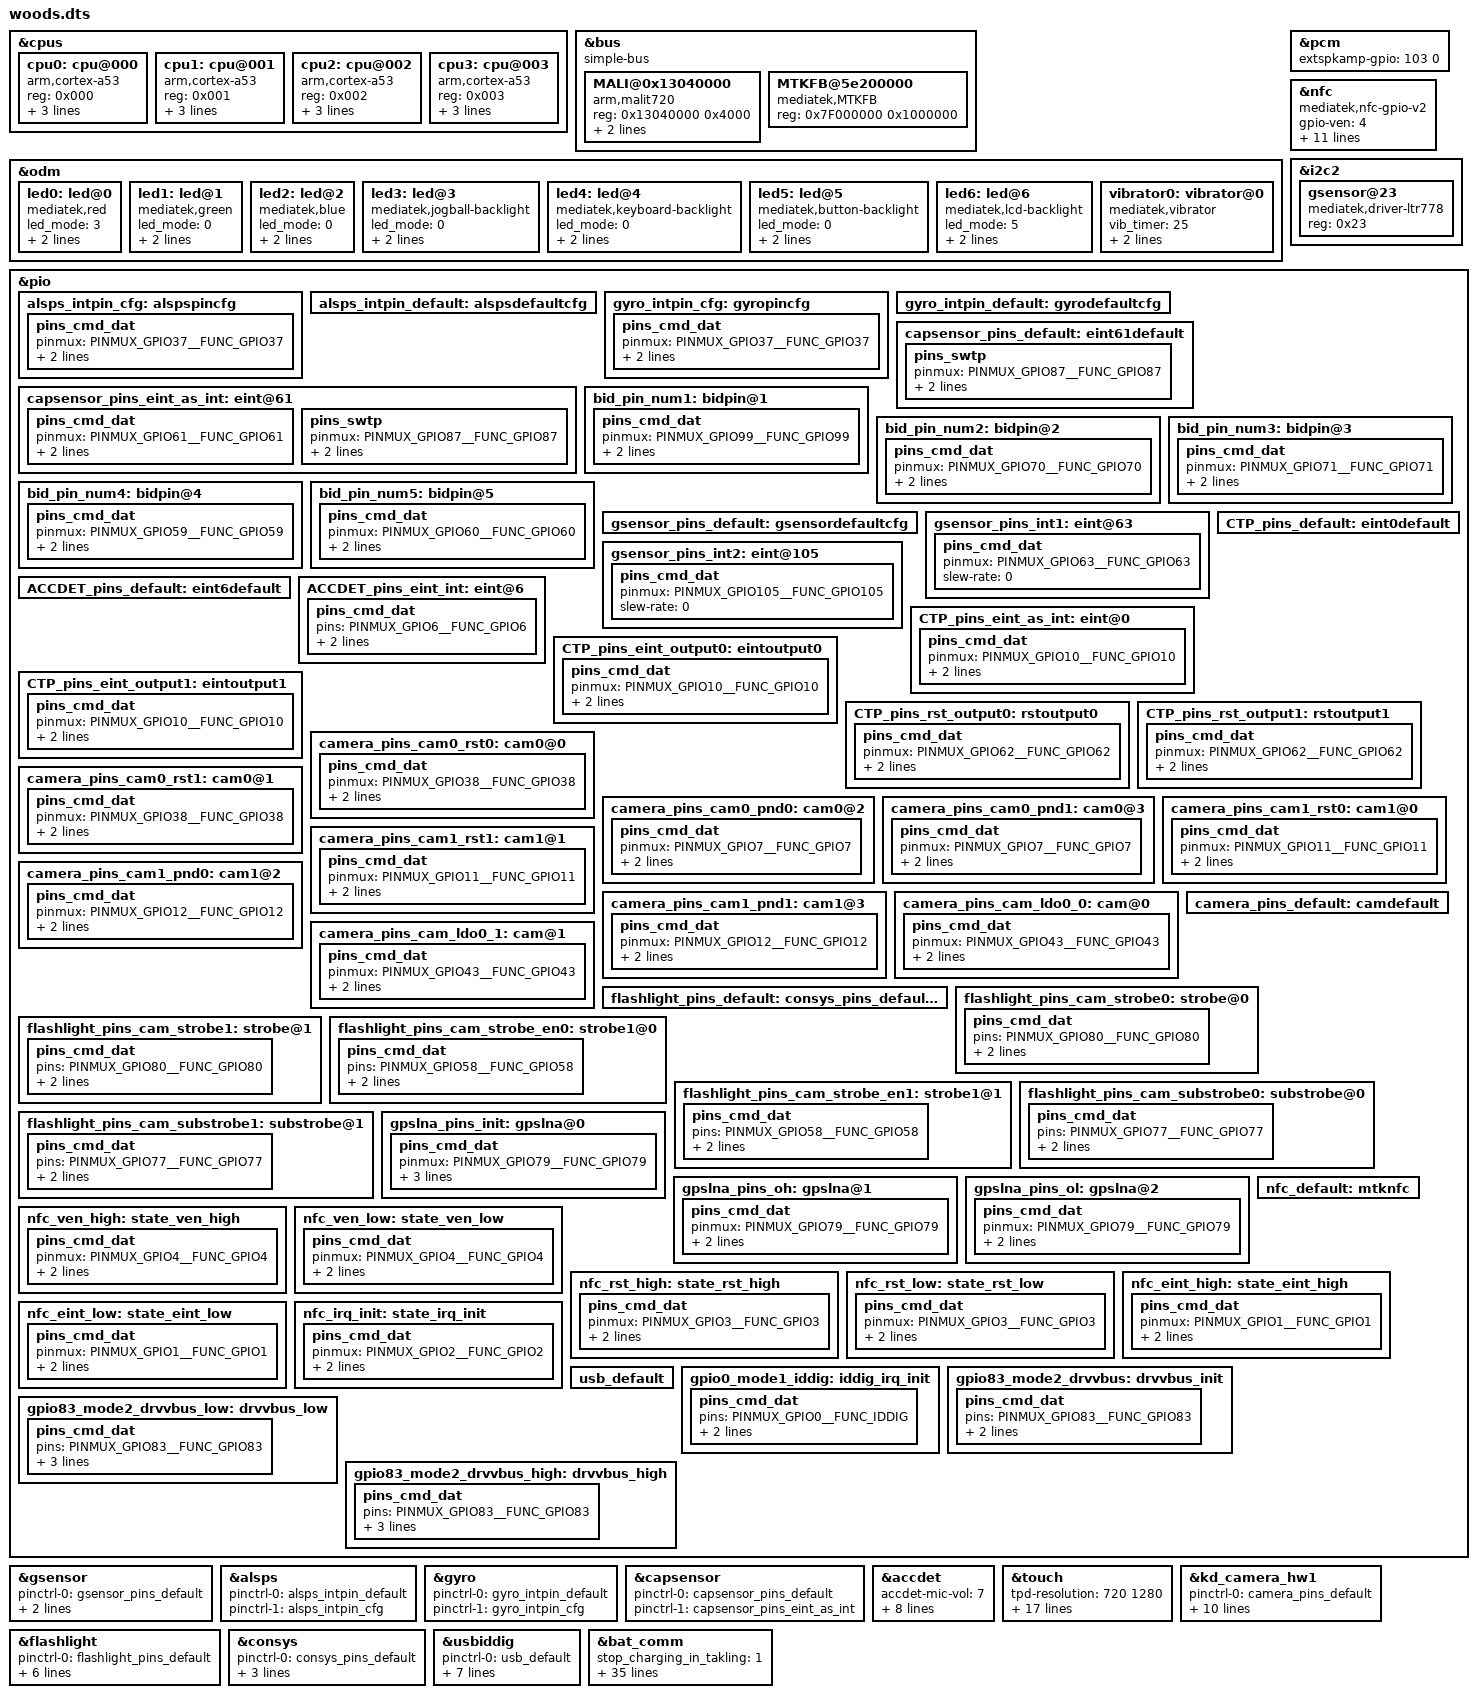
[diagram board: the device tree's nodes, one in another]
#include <generated/autoconf.h>
/dts-v1/;

#include "mt6735m.dts"

&cpus {
	#address-cells = <1>;
	#size-cells = <0>;
	/*enable-method = "mediatek,mt6735-smp"; */

	cpu0: cpu@000 {
		device_type = "cpu";
		compatible = "arm,cortex-a53";
		reg = <0x000>;
		enable-method = "spin-table";
		cpu-release-addr = <0x0 0x40000200>;
		clock-frequency = <1100000000>;
	};

	cpu1: cpu@001 {
		device_type = "cpu";
		compatible = "arm,cortex-a53";
		reg = <0x001>;
		enable-method = "spin-table";
		cpu-release-addr = <0x0 0x40000200>;
		clock-frequency = <1100000000>;
	};

	cpu2: cpu@002 {
		device_type = "cpu";
		compatible = "arm,cortex-a53";
		reg = <0x002>;
		enable-method = "spin-table";
		cpu-release-addr = <0x0 0x40000200>;
		clock-frequency = <1100000000>;
	};

	cpu3: cpu@003 {
		device_type = "cpu";
		compatible = "arm,cortex-a53";
		reg = <0x003>;
		enable-method = "spin-table";
		cpu-release-addr = <0x0 0x40000200>;
		clock-frequency = <1100000000>;
	};
};

&bus {
	compatible = "simple-bus";
	#address-cells = <1>;
	#size-cells = <1>;
	ranges = <0 0 0 0xffffffff>;

	MALI@0x13040000 {
		compatible = "arm,malit720", "arm,mali-t72x", "arm,malit7xx", "arm,mali-midgard";
		reg = <0x13040000 0x4000>;
		interrupts = <0 212 0x8>, <0 211 0x8>, <0 210 0x8>;
		interrupt-names = "JOB", "MMU", "GPU";
		clock-frequency = <550000000>;
	};

	MTKFB@5e200000 {
		compatible = "mediatek,MTKFB";
		reg = <0x7F000000 0x1000000>;
	};
};

&odm {
	led0:led@0 {
		compatible = "mediatek,red";
		led_mode = <3>;
		data = <2>;
		pwm_config = <0 0 0 0 0>;
	};
	led1:led@1 {
		compatible = "mediatek,green";
		led_mode = <0>;
		data = <1>;
		pwm_config = <0 0 0 0 0>;
	};
	led2:led@2 {
		compatible = "mediatek,blue";
		led_mode = <0>;
		data = <1>;
		pwm_config = <0 0 0 0 0>;
	};
	led3:led@3 {
		compatible = "mediatek,jogball-backlight";
		led_mode = <0>;
		data = <1>;
		pwm_config = <0 0 0 0 0>;
	};
	led4:led@4 {
		compatible = "mediatek,keyboard-backlight";
		led_mode = <0>;
		data = <1>;
		pwm_config = <0 0 0 0 0>;
	};
	led5:led@5 {
		compatible = "mediatek,button-backlight";
		led_mode = <0>;
		data = <1>;
		pwm_config = <0 0 0 0 0>;
	};
	led6:led@6 {
		compatible = "mediatek,lcd-backlight";
		led_mode = <5>;
		data = <1>;
		pwm_config = <0 0 0 0 0>;
	};
	vibrator0:vibrator@0 {
		compatible = "mediatek,vibrator";
		vib_timer = <25>;
		vib_limit = <9>;
		vib_vol= <5>;
	};
};

&pcm {
    extspkamp-gpio = <103 0>;
};

&nfc {
    compatible = "mediatek,nfc-gpio-v2";
    gpio-ven = <4>;
    gpio-rst = <3>;
    gpio-eint = <1>;
    gpio-irq = <2>;
};


&i2c2 {
	#address-cells = <1>;
	#size-cells = <0>;
	gsensor@23 {
		compatible = "mediatek,driver-ltr778";
		reg = <0x23>;
		status = "okay";
	};
};

/* sensor gpio standization */
&pio {
	alsps_intpin_cfg: alspspincfg {

		pins_cmd_dat {
			pinmux = <PINMUX_GPIO37__FUNC_GPIO37>;
			slew-rate = <0>;
			bias-pull-up = <00>;
		};
	};

	alsps_intpin_default: alspsdefaultcfg {

	};

	gyro_intpin_cfg: gyropincfg {

		pins_cmd_dat {
			pinmux = <PINMUX_GPIO37__FUNC_GPIO37>;
			slew-rate = <0>;
			bias-pull-down = <00>;
		};
	};

	gyro_intpin_default: gyrodefaultcfg {

	};

	capsensor_pins_default: eint61default {
		pins_swtp {
		    pinmux = <PINMUX_GPIO87__FUNC_GPIO87>;
		    slew-rate = <0>;
		    bias-pull-up = <00>;
		};
	};
	capsensor_pins_eint_as_int: eint@61 {
		pins_cmd_dat {
			pinmux = <PINMUX_GPIO61__FUNC_GPIO61>;
			slew-rate = <0>;
			bias-pull-up = <00>;
		};
        pins_swtp {
            pinmux = <PINMUX_GPIO87__FUNC_GPIO87>;
            slew-rate = <0>;
            bias-pull-up = <00>;
        };
	};

};

&pio {
	bid_pin_num1: bidpin@1 {
	    pins_cmd_dat {
			pinmux = <PINMUX_GPIO99__FUNC_GPIO99>;
			slew-rate = <1>;
			bias-pull-down = <00>;
		};
	};
	bid_pin_num2: bidpin@2 {
	    pins_cmd_dat {
			pinmux = <PINMUX_GPIO70__FUNC_GPIO70>;
			slew-rate = <1>;
			bias-pull-down = <00>;
		};
	};
	bid_pin_num3: bidpin@3 {
	    pins_cmd_dat {
			pinmux = <PINMUX_GPIO71__FUNC_GPIO71>;
			slew-rate = <1>;
			bias-pull-down = <00>;
		};
	};
	bid_pin_num4: bidpin@4{
	    pins_cmd_dat {
			pinmux = <PINMUX_GPIO59__FUNC_GPIO59>;
			slew-rate = <1>;
			bias-pull-down = <00>;
		};
	};
	bid_pin_num5: bidpin@5 {
	    pins_cmd_dat {
			pinmux = <PINMUX_GPIO60__FUNC_GPIO60>;
			slew-rate = <1>;
			bias-pull-down = <00>;
		};
	};
	gsensor_pins_default: gsensordefaultcfg {

	};
	gsensor_pins_int1: eint@63 {
	    pins_cmd_dat {
			pinmux = <PINMUX_GPIO63__FUNC_GPIO63>;
			slew-rate = <0>;
		};
	};

	gsensor_pins_int2: eint@105 {
	    pins_cmd_dat {
			pinmux = <PINMUX_GPIO105__FUNC_GPIO105>;
			slew-rate = <0>;
		};
	};
};
//liupeng@wind-mobi.com 20161121 end

&gsensor {
	pinctrl-names = "pin_default", "pin_state_int1","pin_state_int2";
	pinctrl-0 = <&gsensor_pins_default>;
	pinctrl-1 = <&gsensor_pins_int1>;
	pinctrl-2 = <&gsensor_pins_int2>;
	status = "okay";
};

&alsps {
	pinctrl-names = "pin_default", "pin_cfg";
	pinctrl-0 = <&alsps_intpin_default>;
	pinctrl-1 = <&alsps_intpin_cfg>;
	status = "okay";

};

&gyro {
	pinctrl-names = "pin_default", "pin_cfg";
	pinctrl-0 = <&gyro_intpin_default>;
	pinctrl-1 = <&gyro_intpin_cfg>;
	status = "okay";

};

&capsensor {
	pinctrl-names = "default", "state_eint_as_int";
	pinctrl-0 = <&capsensor_pins_default>;
	pinctrl-1 = <&capsensor_pins_eint_as_int>;
	status = "okay";
};

/* sensor end */

&pio {
	ACCDET_pins_default:eint6default {
	};
	ACCDET_pins_eint_int:eint@6 {
		pins_cmd_dat {
			pins = <PINMUX_GPIO6__FUNC_GPIO6>;
			slew-rate = <0>;
			bias-disable;
		};
	};
};
&accdet {
		accdet-mic-vol = <7>;
		headset-mode-setting = <0x500 0x200 1 0x1F0 0x800 0x800 0x20>;
		accdet-plugout-debounce = <20>;
		/*1:ACC mode, 2:low cost without in bias, 6:low cost with in bias*/
		accdet-mic-mode = <1>; //6
		/*0--MD_MAX--UP_MAX--DW_MAX*/
		headset-three-key-threshold = <0 80 160 500>;
		/*0--MD_MAX--VOICE_MAX--UP_MAX--DW_MAX*/
		headset-four-key-threshold = <0 58 121 192 450>;
		/* ACCDET GPIO standardization ACC mode use */
		pinctrl-names = "default", "state_eint_as_int";
		pinctrl-0 = <&ACCDET_pins_default>;
		pinctrl-1 = <&ACCDET_pins_eint_int>;
		status = "okay";
};
&touch {
	tpd-resolution = <720 1280>;
	use-tpd-button = <0>;
	tpd-key-num = <3>;
	tpd-key-local= <139 172 158 0>;
	tpd-key-dim-local = <90 883 100 40 230 883 100 40 370 883 100 40 0 0 0 0>;
	tpd-max-touch-num = <5>;
	tpd-filter-enable = <1>;
	tpd-filter-pixel-density = <124>;
	tpd-filter-custom-prameters = <0 0 0 0 0 0 0 0 0 0 0 0>;
	tpd-filter-custom-speed = <0 0 0>;
	pinctrl-names = "default", "state_eint_as_int", "state_eint_output0", "state_eint_output1",
		"state_rst_output0", "state_rst_output1";
	pinctrl-0 = <&CTP_pins_default>;
	pinctrl-1 = <&CTP_pins_eint_as_int>;
	pinctrl-2 = <&CTP_pins_eint_output0>;
	pinctrl-3 = <&CTP_pins_eint_output1>;
	pinctrl-4 = <&CTP_pins_rst_output0>;
	pinctrl-5 = <&CTP_pins_rst_output1>;
	status = "okay";
};
&pio {
	CTP_pins_default: eint0default {
	};
	CTP_pins_eint_as_int: eint@0 {
		pins_cmd_dat {
			pinmux = <PINMUX_GPIO10__FUNC_GPIO10>;
			slew-rate = <0>;
			//	bias-disable;
			bias-pull-up = <00>;
		};
	};
	CTP_pins_eint_output0: eintoutput0 {
		pins_cmd_dat {
			pinmux = <PINMUX_GPIO10__FUNC_GPIO10>;
			slew-rate = <1>;
			output-low;
		};
	};
	CTP_pins_eint_output1: eintoutput1 {
		pins_cmd_dat {
			pinmux = <PINMUX_GPIO10__FUNC_GPIO10>;
			slew-rate = <1>;
			output-high;
		};
	};
	CTP_pins_rst_output0: rstoutput0 {
		pins_cmd_dat {
			pinmux = <PINMUX_GPIO62__FUNC_GPIO62>;
			slew-rate = <1>;
			output-low;
		};
	};
	CTP_pins_rst_output1: rstoutput1 {
		pins_cmd_dat {
			pinmux = <PINMUX_GPIO62__FUNC_GPIO62>;
			slew-rate = <1>;
			output-high;
		};
	};
};
/* TOUCH end */
/* CAMERA GPIO standardization */
&pio {
	camera_pins_cam0_rst0: cam0@0 {
		pins_cmd_dat {
			pinmux = <PINMUX_GPIO38__FUNC_GPIO38>;/*GPIO_CAMERA_CMRST_PIN*/
			slew-rate = <1>; /*direction 0:in, 1:out*/
			output-low;/*direction out used only. output_low or high*/
		};
	};
	camera_pins_cam0_rst1: cam0@1 {
		pins_cmd_dat {
			pinmux = <PINMUX_GPIO38__FUNC_GPIO38>;/*GPIO_CAMERA_CMRST_PIN*/
			slew-rate = <1>;
			output-high;
		};
	};
	camera_pins_cam0_pnd0: cam0@2 {
		pins_cmd_dat {
			pinmux = <PINMUX_GPIO7__FUNC_GPIO7>;/*GPIO_CAMERA_CMPDN_PIN*/
			slew-rate = <1>;
			output-low;
		};
	};
	camera_pins_cam0_pnd1: cam0@3 {
		pins_cmd_dat {
			pinmux = <PINMUX_GPIO7__FUNC_GPIO7>;/*GPIO_CAMERA_CMPDN_PIN*/
			slew-rate = <1>;
			output-high;
		};
	};
	camera_pins_cam1_rst0: cam1@0 {
		pins_cmd_dat {
			pinmux = <PINMUX_GPIO11__FUNC_GPIO11>;/*GPIO_CAMERA_CMRST1_PIN*/
			slew-rate = <1>; /*direction 0:in, 1:out*/
			output-low;/*direction out used only. output_low or high*/
		};
	};
	camera_pins_cam1_rst1: cam1@1 {
		pins_cmd_dat {
			pinmux = <PINMUX_GPIO11__FUNC_GPIO11>;/*GPIO_CAMERA_CMRST1_PIN*/
			slew-rate = <1>;
			output-high;
		};
	};
	camera_pins_cam1_pnd0: cam1@2 {
		pins_cmd_dat {
			pinmux = <PINMUX_GPIO12__FUNC_GPIO12>;/*GPIO_CAMERA_CMPDN1_PIN*/
			slew-rate = <1>;
			output-low;
		};
	};
	camera_pins_cam1_pnd1: cam1@3 {
		pins_cmd_dat {
			pinmux = <PINMUX_GPIO12__FUNC_GPIO12>;/*GPIO_CAMERA_CMPDN1_PIN*/
			slew-rate = <1>;
			output-high;
		};
	};
	camera_pins_cam_ldo0_0: cam@0 {
		pins_cmd_dat {
			pinmux = <PINMUX_GPIO43__FUNC_GPIO43>;/*GPIO_SPI_MOSI_PIN*/
			slew-rate = <1>;
			output-low;
		};
	};
	camera_pins_cam_ldo0_1: cam@1 {
		pins_cmd_dat {
			pinmux = <PINMUX_GPIO43__FUNC_GPIO43>;/*GPIO_SPI_MOSI_PIN*/
			slew-rate = <1>;
			output-high;
		};
	};
	camera_pins_default: camdefault {
	};

};

&kd_camera_hw1 {
	pinctrl-names = "default", "cam0_rst0", "cam0_rst1", "cam0_pnd0", "cam0_pnd1",
			"cam1_rst0", "cam1_rst1", "cam1_pnd0", "cam1_pnd1","cam_ldo0_0", "cam_ldo0_1";
	pinctrl-0 = <&camera_pins_default>;
	pinctrl-1 = <&camera_pins_cam0_rst0>;
	pinctrl-2 = <&camera_pins_cam0_rst1>;
	pinctrl-3 = <&camera_pins_cam0_pnd0>;
	pinctrl-4 = <&camera_pins_cam0_pnd1>;
	pinctrl-5 = <&camera_pins_cam1_rst0>;
	pinctrl-6 = <&camera_pins_cam1_rst1>;
	pinctrl-7 = <&camera_pins_cam1_pnd0>;
	pinctrl-8 = <&camera_pins_cam1_pnd1>;
	pinctrl-9 = <&camera_pins_cam_ldo0_0>;
	pinctrl-10 = <&camera_pins_cam_ldo0_1>;
	status = "okay";

};
/* CAMERA GPIO end */
//wangkangmin@wind-mobi.com 20170215 begin
/* FLASHLIGHT GPIO begin */
&pio{
	flashlight_pins_default: default{
	};
	flashlight_pins_cam_strobe0: strobe@0 {
	    pins_cmd_dat {
			pins = <PINMUX_GPIO80__FUNC_GPIO80>;/*GPIO_CAMERA_FLASH_EN_PIN*/
			slew-rate = <1>;
			output-low;
		};
	};
	flashlight_pins_cam_strobe1: strobe@1 {
	    pins_cmd_dat {
			pins = <PINMUX_GPIO80__FUNC_GPIO80>;/*GPIO_CAMERA_FLASH_EN_PIN*/
			slew-rate = <1>;
			output-high;
		};
	};
	flashlight_pins_cam_strobe_en0: strobe1@0 {
	    pins_cmd_dat {
			pins = <PINMUX_GPIO58__FUNC_GPIO58>;/*GPIO_CAMERA_FLASH_EN_PIN*/
			slew-rate = <1>;
			output-low;
		};
	};
	flashlight_pins_cam_strobe_en1: strobe1@1 {
	    pins_cmd_dat {
			pins = <PINMUX_GPIO58__FUNC_GPIO58>;/*GPIO_CAMERA_FLASH_EN_PIN*/
			slew-rate = <1>;
			output-high;
		};
	};
	flashlight_pins_cam_substrobe0: substrobe@0 {
	    pins_cmd_dat {
			pins = <PINMUX_GPIO77__FUNC_GPIO77>;/*GPIO_CAMERA_FLASH_MODE_PIN*/
			slew-rate = <1>;
			output-low;
		};
	};
	flashlight_pins_cam_substrobe1: substrobe@1 {
	    pins_cmd_dat {
			pins = <PINMUX_GPIO77__FUNC_GPIO77>;/*GPIO_CAMERA_FLASH_MODE_PIN*/
			slew-rate = <1>;
			output-high;
		};
	};
};

&flashlight {
	pinctrl-names = "default","cam_strobe0","cam_strobe1","cam_strobe_en0",
					"cam_strobe_en1","cam_substrobe0","cam_substrobe1";

	pinctrl-0 = <&flashlight_pins_default>;
	pinctrl-1 = <&flashlight_pins_cam_strobe0>;
	pinctrl-2 = <&flashlight_pins_cam_strobe1>;
	pinctrl-3 = <&flashlight_pins_cam_strobe_en0>;
	pinctrl-4 = <&flashlight_pins_cam_strobe_en1>;
	pinctrl-5 = <&flashlight_pins_cam_substrobe0>;
	pinctrl-6 = <&flashlight_pins_cam_substrobe1>;

	status = "okay";
};
/* FLASHLIGHT GPIO end * /
//wangkangmin@wind-mobi.com 20170215 end

/* CONSYS GPIO standardization */
&pio {
	consys_pins_default: default {

	};

	gpslna_pins_init: gpslna@0 {

		pins_cmd_dat {
			pinmux = <PINMUX_GPIO79__FUNC_GPIO79>;
			slew-rate = <0>;
			bias-disable;
			output-low;
		};
	};

	gpslna_pins_oh: gpslna@1 {

		pins_cmd_dat {
			pinmux = <PINMUX_GPIO79__FUNC_GPIO79>;
			slew-rate = <1>;
			output-high;
		};
	};

	gpslna_pins_ol: gpslna@2 {

		pins_cmd_dat {
			pinmux = <PINMUX_GPIO79__FUNC_GPIO79>;
			slew-rate = <1>;
			output-low;
		};
	};

};

&consys {
	pinctrl-names = "default", "gps_lna_state_init", "gps_lna_state_oh", "gps_lna_state_ol";
	pinctrl-0 = <&consys_pins_default>;
	pinctrl-1 = <&gpslna_pins_init>;
	pinctrl-2 = <&gpslna_pins_oh>;
	pinctrl-3 = <&gpslna_pins_ol>;
	status = "okay";

};
/* CONSYS end */

/* NFC GPIO standardization */
&pio {
	nfc_default: mtknfc {

	};

	nfc_ven_high: state_ven_high {
		pins_cmd_dat {
			pinmux = <PINMUX_GPIO4__FUNC_GPIO4>;
			slew-rate = <1>;
			output-high;
		};
	};

	nfc_ven_low: state_ven_low {
		pins_cmd_dat {
			pinmux = <PINMUX_GPIO4__FUNC_GPIO4>;
			slew-rate = <1>;
			output-low;
		};
	};

	nfc_rst_high: state_rst_high {
		pins_cmd_dat {
			pinmux = <PINMUX_GPIO3__FUNC_GPIO3>;
			slew-rate = <1>;
			output-high;
		};
	};

	nfc_rst_low: state_rst_low {
		pins_cmd_dat {
			pinmux = <PINMUX_GPIO3__FUNC_GPIO3>;
			slew-rate = <1>;
			output-low;
		};
	};

	nfc_eint_high: state_eint_high {
		pins_cmd_dat {
			pinmux = <PINMUX_GPIO1__FUNC_GPIO1>;
			slew-rate = <1>;
			output-high;
		};
	};

	nfc_eint_low: state_eint_low {
		pins_cmd_dat {
			pinmux = <PINMUX_GPIO1__FUNC_GPIO1>;
			slew-rate = <1>;
			output-low;
		};
	};

	nfc_irq_init: state_irq_init {
		pins_cmd_dat {
			pinmux = <PINMUX_GPIO2__FUNC_GPIO2>;
			slew-rate = <0>;
			bias-pull-down = <00>;
		};
	};
};

&nfc {
	pinctrl-names = "mtknfc", "ven_high", "ven_low", "rst_high", "rst_low", "eint_high", "eint_low", "irq_init";
	pinctrl-0 = <&nfc_default>;
	pinctrl-1 = <&nfc_ven_high>;
	pinctrl-2 = <&nfc_ven_low>;
	pinctrl-3 = <&nfc_rst_high>;
	pinctrl-4 = <&nfc_rst_low>;
	pinctrl-5 = <&nfc_eint_high>;
	pinctrl-6 = <&nfc_eint_low>;
	pinctrl-7 = <&nfc_irq_init>;
	status = "okay";
};
/* NFC end */

/* USB GPIO Kernal Standardization start */
&pio {
	usb_default: usb_default {
	};

	gpio0_mode1_iddig: iddig_irq_init {
		pins_cmd_dat {
			pins = <PINMUX_GPIO0__FUNC_IDDIG>;
			slew-rate = <0>;
			bias-pull-up = <00>;
		};
	};

	gpio83_mode2_drvvbus: drvvbus_init {
		pins_cmd_dat {
			pins = <PINMUX_GPIO83__FUNC_GPIO83>;
			slew-rate = <1>;
			bias-pull-down = <00>;
		};
	};

	gpio83_mode2_drvvbus_low: drvvbus_low {
		pins_cmd_dat {
			pins = <PINMUX_GPIO83__FUNC_GPIO83>;
			slew-rate = <1>;
			output-low;
			bias-pull-down = <00>;
		};
	};

	gpio83_mode2_drvvbus_high: drvvbus_high {
		pins_cmd_dat {
			pins = <PINMUX_GPIO83__FUNC_GPIO83>;
			slew-rate = <1>;
			output-high;
			bias-pull-down = <00>;
		};
	};
};

&usbiddig {
	pinctrl-names = "usb_default", "iddig_irq_init", "drvvbus_init", "drvvbus_low", "drvvbus_high";
	pinctrl-0 = <&usb_default>;
	pinctrl-1 = <&gpio0_mode1_iddig>;
	pinctrl-2 = <&gpio83_mode2_drvvbus>;
	pinctrl-3 = <&gpio83_mode2_drvvbus_low>;
	pinctrl-4 = <&gpio83_mode2_drvvbus_high>;
	interrupt-parent = <&eintc>;
	interrupts = <0 IRQ_TYPE_LEVEL_LOW>;
	debounce = <9 0>;
	status = "okay";
};

/* USB GPIO Kernal Standardization end */

&bat_comm {
	/* cust_charging.h */
	/* stop charging while in talking mode */
	stop_charging_in_takling = <1 >;
	talking_recharge_voltage = <3800 >;
	talking_sync_time = <60 >;

	/* Battery Temperature Protection */
	mtk_temperature_recharge_support = <1 >;
	max_charge_temperature = <59 >;
	max_charge_temperature_minus_x_degree = <58 >;
	min_charge_temperature = <(-19) >;
	min_charge_temperature_plus_x_degree = <(-18) >;
	err_charge_temperature = <0xff >;

	/* Linear Charging Threshold */
	v_pre2cc_thres = <3400 >;	/* unit: mV */
	v_cc2topoff_thres = <4050 >;
	recharging_voltage = <4110 >;
	charging_full_current = <100 >;	/* unit: mA */

	/* Charging Current Setting */
	config_usb_if = <0 >;
	usb_charger_current_suspend = <0 >;	/* Unit: 0.01 mA */
	usb_charger_current_unconfigured = <7000 >;	/* Unit: 0.01 mA */
	usb_charger_current_configured = <50000 >;	/* Unit: 0.01 mA */
	usb_charger_current = <102400 >;	/* Unit: 0.01 mA */
	ac_charger_input_current = <200000 >;	/* Unit: 0.01 mA */
	ac_charger_input_current_AP_EMEA = <100000 >;	/* Unit: 0.01 mA */
	ac_charger_current = <179200 >;	/* Unit: 0.01 mA */
	ac_charger_current_AP_EMEA = <102400 >;	/* Unit: 0.01 mA */
	non_std_ac_charger_current = <50000 >;	/* Unit: 0.01 mA */
	charging_host_charger_current = <65000 >;	/* Unit: 0.01 mA */
	apple_0_5a_charger_current = <50000 >;	/* Unit: 0.01 mA */
	apple_1_0a_charger_current = <65000 >;	/* Unit: 0.01 mA */
	apple_2_1a_charger_current = <80000 >;	/* Unit: 0.01 mA */

	/* charger error check */
	bat_low_temp_protect_enable = <1 >;/*qiantao@wind-mobi.com*/
	v_charger_enable = <1 >;	/* 1:on , 0:off */
	v_charger_max = <6500 >;	/* unit: mV */
	v_charger_min = <4400 >;

	/*  Tracking TIME */
	onehundred_percent_tracking_time = <10 >;	/* Unit: second */
	npercent_tracking_time = <20 >;	/* Unit: second */
	sync_to_real_tracking_time = <60 >;	/* Unit: second */
	v_0percent_tracking = <3450 >;	/* Unit: mV */

	/* High battery support */
	high_battery_voltage_support = <1>;/*qiantao@wind-mobi.com*/
};

#include <woods/cust.dtsi>
